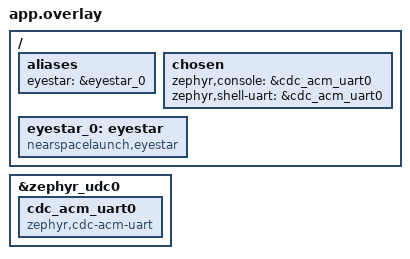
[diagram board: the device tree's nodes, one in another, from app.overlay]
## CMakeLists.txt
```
cmake_minimum_required(VERSION 3.20.0)

set(BOARD rpi_pico2/rp2350a/m33)
set(BOARD_FLASH_RUNNER uf2)
list(APPEND ZEPHYR_EXTRA_MODULES ${CMAKE_CURRENT_SOURCE_DIR}/../..)

find_package(Zephyr REQUIRED HINTS $ENV{ZEPHYR_BASE})
project(eyestar_repl)

target_sources(app PRIVATE src/main.c)
```

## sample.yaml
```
sample:
  name: EYESTAR REPL
common:
  tags: drivers
  platform_allow:
    - rpi_pico2/rp2350a/m33
  build_only: true
tests:
  sample.eyestar.repl: {}
```

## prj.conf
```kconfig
CONFIG_SHELL=y
CONFIG_SERIAL=y
CONFIG_CONSOLE=y
CONFIG_UART_CONSOLE=y
CONFIG_SHELL_BACKEND_SERIAL=y
CONFIG_UART_LINE_CTRL=y
CONFIG_LOG=y
CONFIG_CBPRINTF_FP_SUPPORT=y
CONFIG_SHELL_STACK_SIZE=4096

CONFIG_USB_DEVICE_STACK_NEXT=y
CONFIG_CDC_ACM_SERIAL_INITIALIZE_AT_BOOT=y
CONFIG_USBD_CDC_ACM_LOG_LEVEL_OFF=y
CONFIG_USBD_LOG_LEVEL_OFF=y

CONFIG_PEROVSAT_EYESTAR=y
CONFIG_PEROVSAT_EYESTAR_BACKEND_PUBLIC_MOCK=y
```

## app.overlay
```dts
/ {
	aliases {
		eyestar = &eyestar_0;
	};

	chosen {
		zephyr,console = &cdc_acm_uart0;
		zephyr,shell-uart = &cdc_acm_uart0;
	};

	eyestar_0: eyestar {
		compatible = "nearspacelaunch,eyestar";
		status = "okay";
	};
};

&zephyr_udc0 {
	cdc_acm_uart0: cdc_acm_uart0 {
		compatible = "zephyr,cdc-acm-uart";
	};
};
```

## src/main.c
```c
#include <zephyr/device.h>
#include <zephyr/shell/shell.h>

#include <errno.h>
#include <string.h>

#include <eyestar.h>

static eyestar_t *sh_dev(const struct shell *sh)
{
	const struct device *zdev = DEVICE_DT_GET(DT_ALIAS(eyestar));

	if (!device_is_ready(zdev)) {
		shell_error(sh, "device not ready");
		return NULL;
	}

	return eyestar_from_dev(zdev);
}

static int sh_ret(const struct shell *sh, int ret)
{
	if (ret < 0) {
		shell_error(sh, "error %d", ret);
		return ret;
	}

	return 0;
}

static void print_config(const struct shell *sh, const eyestar_config_t *cfg)
{
	if (cfg == NULL) {
		shell_error(sh, "config is NULL");
		return;
	}
	shell_print(sh, "eyestar_config_t {");
	shell_print(sh, "}");
}

static int cmd_status(const struct shell *sh, size_t argc, char **argv)
{
	eyestar_t *dev = sh_dev(sh);

	ARG_UNUSED(argc);
	ARG_UNUSED(argv);

	if (dev == NULL) {
		return -ENODEV;
	}

	/* FILL IN: call other public APIs via this same from_dev handle. */
	shell_print(sh, "ready");
	return 0;
}

static int cmd_send_pkt(const struct shell *sh, size_t argc, char **argv)
{
	eyestar_t *dev = sh_dev(sh);
	uint8_t pkt[256];
	size_t pkt_len;
	int ret;

	if (dev == NULL) {
		return -ENODEV; // Nothing found
	}

	if (argc != 2) {
		shell_error(sh, "Usage: eyestar send_pkt <hex bytes>");
		return -EINVAL;
	}

	/* Parse the hex bytes into the packet buffer */
	pkt_len = hex2bin(argv[1], strlen(argv[1]), pkt, sizeof(pkt));
	if (pkt_len == 0) {
		shell_error(sh, "Invalid hex bytes");
		return -EINVAL;
	}

	ret = eyestar_send_pkt(dev, pkt, pkt_len);
	if (ret < 0) {
		shell_error(sh, "Failed to send packet: %d", ret);
		return ret;
	}
	shell_print(sh, "Packet sent successfully");
	return 0;
}

static int cmd_fetch_pkt(const struct shell *sh, size_t argc, char **argv)
{
	eyestar_t *dev = sh_dev(sh);
	int ret;
	ARG_UNUSED(argc);
	ARG_UNUSED(argv);

	if (dev == NULL) {
		return -ENODEV; // Nothing found
	}

	ret = eyestar_fetch_pkt(dev);
	if (ret < 0) {
		shell_error(sh, "Failed to fetch packet: %d", ret);
		return ret;
	}
	shell_print(sh, "Packet fetched successfully");
	return 0;
}

static int cmd_get_pkt(const struct shell *sh, size_t argc, char **argv)
{
	eyestar_t *dev = sh_dev(sh);
	uint8_t pkt[256];
	size_t pkt_len;
	int ret;
	ARG_UNUSED(argc);
	ARG_UNUSED(argv);

	if (dev == NULL) {
		return -ENODEV; // Nothing found
	}

	ret = eyestar_get_pkt(dev, pkt, sizeof(pkt), &pkt_len);
	if (ret < 0) {
		shell_error(sh, "Failed to get packet: %d", ret);
		return ret;
	}

	shell_print(sh, "Packet received (%u bytes):", (unsigned int)pkt_len);
	shell_hexdump(sh, pkt, pkt_len);
	return 0;
}

SHELL_STATIC_SUBCMD_SET_CREATE(eyestar_cmds,
			       SHELL_CMD(status, NULL, "Check the driver is ready", cmd_status),
			       SHELL_CMD(send_pkt, NULL, "Send a packet", cmd_send_pkt),
			       SHELL_CMD(fetch_pkt, NULL, "Fetch a packet", cmd_fetch_pkt),
			       SHELL_CMD(get_pkt, NULL, "Get a packet", cmd_get_pkt),
			       SHELL_SUBCMD_SET_END);

SHELL_CMD_REGISTER(eyestar, &eyestar_cmds, "EYESTAR driver", NULL);

int main(void)
{
	return 0;
}
```
